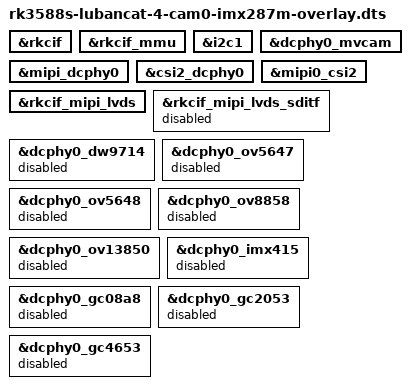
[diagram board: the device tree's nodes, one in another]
// SPDX-License-Identifier: (GPL-2.0+ OR MIT)
/dts-v1/;
/plugin/;

/ {
	fragment@0 {
		target = <&rkcif>;
		__overlay__ {
			status = "okay";
		};
	};
	fragment@1 {
		target = <&rkcif_mmu>;
		__overlay__ {
			status = "okay";
		};
	};
	fragment@2 {
		target = <&i2c1>;
		__overlay__ {
			status = "okay";
		};
	};
	fragment@3 {
		target = <&dcphy0_mvcam>;
		__overlay__ {
			status = "okay";
		};
	};
	fragment@4 {
		target = <&mipi_dcphy0>;
		__overlay__ {
			status = "okay";
		};
	};
	fragment@5 {
		target = <&csi2_dcphy0>;
		__overlay__ {
			status = "okay";
		};
	};
	fragment@6 {
		target = <&mipi0_csi2>;
		__overlay__ {
			status = "okay";
		};
	};
	fragment@7 {
		target = <&rkcif_mipi_lvds>;
		__overlay__ {
			status = "okay";
		};
	};
	fragment@8 {
		target = <&rkcif_mipi_lvds_sditf>;
		__overlay__ {
			status = "disabled";
		};
	};
	fragment@9 {
		target = <&dcphy0_dw9714>;
		__overlay__ {
			status = "disabled";
		};
	};
	fragment@10 {
		target = <&dcphy0_ov5647>;
		__overlay__ {
			status = "disabled";
		};
	};
	fragment@11 {
		target = <&dcphy0_ov5648>;
		__overlay__ {
			status = "disabled";
		};
	};
	fragment@12 {
		target = <&dcphy0_ov8858>;
		__overlay__ {
			status = "disabled";
		};
	};
	fragment@13 {
		target = <&dcphy0_ov13850>;
		__overlay__ {
			status = "disabled";
		};
	};
	fragment@14 {
		target = <&dcphy0_imx415>;
		__overlay__ {
			status = "disabled";
		};
	};
	fragment@15 {
		target = <&dcphy0_gc08a8>;
		__overlay__ {
			status = "disabled";
		};
	};
	fragment@16 {
		target = <&dcphy0_gc2053>;
		__overlay__ {
			status = "disabled";
		};
	};
	fragment@17 {
		target = <&dcphy0_gc4653>;
		__overlay__ {
			status = "disabled";
		};
	};
};
